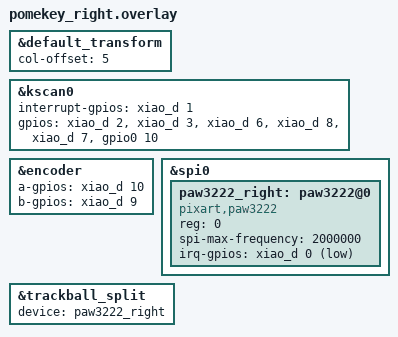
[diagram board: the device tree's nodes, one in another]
#include "pomekey.dtsi"

&default_transform {
    col-offset = <5>;
};

&kscan0 {
    interrupt-gpios = <&xiao_d 1 (GPIO_ACTIVE_HIGH | GPIO_PULL_DOWN)>; // gpio_interrupt: P0.03
    gpios
        = <&xiao_d 2 GPIO_ACTIVE_HIGH>   // gpio0: P0.28
        , <&xiao_d 3 GPIO_ACTIVE_HIGH>   // gpio1: P0.29
        , <&xiao_d 6 GPIO_ACTIVE_HIGH>   // gpio2: P1.11
        , <&xiao_d 8 GPIO_ACTIVE_HIGH>   // gpio3: P1.13
        , <&xiao_d 7 GPIO_ACTIVE_HIGH>   // gpio4: P1.12
        , <&gpio0 10 GPIO_ACTIVE_HIGH>   // gpio5: P0.10 (NFC2)
        ;
};

&encoder {
    status = "okay";
    a-gpios = <&xiao_d 10 (GPIO_ACTIVE_HIGH | GPIO_PULL_UP)>; // P1.15
    b-gpios = <&xiao_d 9 (GPIO_ACTIVE_HIGH | GPIO_PULL_UP)>;  // P1.14
};

&spi0 {
    status = "okay";
    paw3222_right: paw3222@0 {
        compatible = "pixart,paw3222";
        reg = <0>;
        spi-max-frequency = <2000000>;
        irq-gpios = <&xiao_d 0 (GPIO_ACTIVE_LOW | GPIO_PULL_UP)>; // MOTION: P0.02
    };
};

// ペリフェラル側のセンサーをスプリット転送用ノードに紐付け
&trackball_split {
    status = "okay";
    device = <&paw3222_right>;
};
